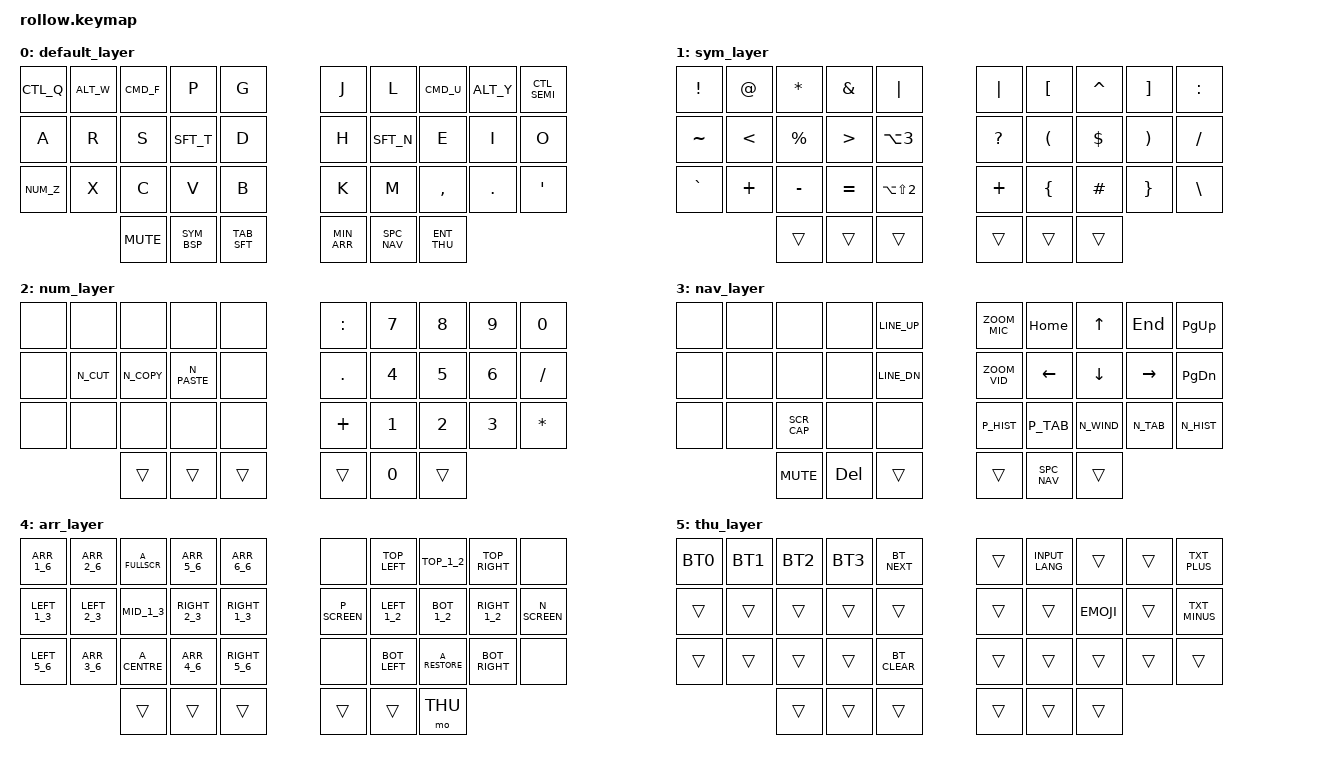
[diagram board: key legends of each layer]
#include <behaviors.dtsi>
#include <dt-bindings/zmk/keys.h>
#include <dt-bindings/zmk/bt.h>

#include "definitions.dtsi"
#include "homerow.dtsi"
#include "combos.dtsi"
#include "unicode.dtsi"
#include "tapdances.dtsi"

/ {
        chosen {
                zmk,matrix_transform = &five_column_transform;
        };

        keymap {
                compatible = "zmk,keymap";

                default_layer {
                        bindings = <
/**
 *      ,-----------------------------------------------------.         .------------------------------------------------------.
 *      |   Q     |    W     |    F     |    P     |    G     |         |    J     |    L     |    U     |    Y     |    ;     |
 *      |  CTRL   |   ALT    |   CMD    |          |          |         |          |          |   CMD    |   ALT    |   CTRL   |
 *      -------------------------------------------------------         --------------------------------------------------------
 *      |   A     |    R     |    S     |    T     |    D     |         |    H     |    N     |    E     |    I     |    O     |
 *      |         |          |          |  Shift   |          |         |          |  Shift   |          |          |          |
 *      -------------------------------------------------------         --------------------------------------------------------
 *      |   Z     |    X     |    C     |    V     |    B     |         |    K     |    M     |    ,     |    .     |    '     |
 *      |  NUM    |          |          |          |          |         |          |          |          |          |          |
 *      -------------------------------------------------------         --------------------------------------------------------
 *                           |   Mute   |   BSP    |   TAB    |         |    -     |  Space   | ENT_THU  |
 *                           |----------|   SYM    |   SFT    |         |   Arr    |   NAV    |----------|
 *                           |   Vol +  |---------------------'         `---------------------|  Right   |
 *                           |   Vol -  |                                                     |  Left    |
 *                           `----------'                                                     `----------'
 **/

        CTL_Q      ALT_W      CMD_F      &kp P      &kp G               &kp J      &kp L      CMD_U      ALT_Y      CTL_SEMI
        &kp A      &kp R      &kp S      SFT_T      &kp D               &kp H      SFT_N      &kp E      &kp I      &kp O
        NUM_Z      &kp X      &kp C      &kp V      &kp B               &kp K      &kp M      &kp COMMA  &kp DOT    &kp SQT
                              &kp C_MUTE SYM_BSP    TAB_SFT             MIN_ARR    SPC_NAV    ENT_THU
                        >;
                        sensor-bindings = <
                                &inc_dec_kp C_VOL_UP C_VOL_DN           &inc_dec_kp RIGHT LEFT
                        >;
                };
                
                sym_layer {
                        bindings = <
/**
 *      ,-----------------------------------------------------.         .------------------------------------------------------.
 *      |   !     |    @     |    *     |    &     |    |     |         |    |     |    [     |    ^     |    ]     |    :     |
 *      |         |          |          |          |          |         |          |          |          |          |          |
 *      -------------------------------------------------------         --------------------------------------------------------
 *      |   ~     |    <     |    %     |    >     |    £     |         |    ?     |    (     |    $     |    )     |    /     |
 *      |         |          |          |          |          |         |          |          |          |          |          |
 *      -------------------------------------------------------         --------------------------------------------------------
 *      |   `     |    +     |    -     |    =     |    €     |         |    +     |    {     |    #     |    }     |    \     |
 *      |         |          |          |          |          |         |          |          |          |          |          |
 *      -------------------------------------------------------         --------------------------------------------------------
 *                           |    NUM   |   BSP    |   TAB    |         |    -     |  Space   |  Enter   |
 *                           |----------|   SYM    |   SFT    |         |   Arr    |   NAV    |----------|
 *                           |    Up    |---------------------'         `---------------------| Page Up  |
 *                           |   Down   |                                                     | Page Down|
 *                           `----------'                                                     `----------'
 **/
 
        &kp EXCL   &kp AT     &kp ASTRK  &kp AMPS   &kp PIPE            &kp PIPE   &kp LBKT   &kp CARET  &kp RBKT   &kp COLON
        &kp TILDE  &kp LT     &kp PRCNT  &kp GT     &kp LA(N3)          &kp QMARK  &kp LPAR   &kp DLLR   &kp RPAR   &kp FSLH
        &kp GRAVE  &kp PLUS   &kp MINUS  &kp EQUAL  &kp LA(LS(N2))      &kp PLUS   &kp LBRC   &kp HASH   &kp RBRC   &kp BSLH
                              &trans     &trans     &trans              &trans     &trans     &trans
                        >;
                        sensor-bindings = <
                                &inc_dec_kp DOWN UP                     &inc_dec_kp PAGE_UP PAGE_DOWN
                        >;
                };

                num_layer {
                        bindings = <
/**
 *      ,-----------------------------------------------------.         .------------------------------------------------------.
 *      |         |          |          |          |          |         |    :     |    7     |    8     |    9     |    0     |
 *      |         |          |          |          |          |         |          |          |          |          |          |
 *      -------------------------------------------------------         --------------------------------------------------------
 *      |         |   CUT    |   COPY   |  PASTE   |          |         |    .     |    4     |    5     |    6     |    /     |
 *      |         |          |          |          |          |         |          |          |          |          |          |
 *      -------------------------------------------------------         --------------------------------------------------------
 *      |  NUM    |          |          |          |          |         |    +     |    1     |    2     |    3     |    *     |
 *      |         |          |          |          |          |         |          |          |          |          |          |
 *      -------------------------------------------------------         --------------------------------------------------------
 *                           |    NUM   |   BSP    |   TAB    |         |    -     |    0     |  Enter   |
 *                           |----------|   SYM    |   SFT    |         |   Arr    |          |----------|
 *                           |    Up    |---------------------'         `---------------------|  Right   |
 *                           |   Down   |                                                     |  Left    |
 *                           `----------'                                                     `----------'
 **/
 
        &none      &none      &none      &none      &none               &kp COLON  &kp N7     &kp N8     &kp N9     &kp N0 
        &none      N_CUT      N_COPY     N_PASTE    &none               &kp DOT    &kp N4     &kp N5     &kp N6     &kp FSLH 
        &none      &none      &none      &none      &none               &kp PLUS   &kp N1     &kp N2     &kp N3     &kp ASTRK
                              &trans     &trans     &trans              &trans     &kp N0     &trans
                        >;
                        sensor-bindings = <
                                &inc_dec_kp DOWN UP                     &inc_dec_kp RIGHT LEFT
                        >;
                };

                nav_layer {
                        bindings = <
/**
 *      ,-----------------------------------------------------.         .------------------------------------------------------.
 *      |         |          |          |          |  Xcode   |         |  Zoom    |   Home   |    Up    |   End    | Page Up  |
 *      |         |          |          |          |  Line Up |         |  Mic     |          |          |          |          |
 *      -------------------------------------------------------         --------------------------------------------------------
 *      |         |          |          |          |  Xcode   |         |  Zoom    |   Left   |   Down   |  Right   | Page Dn  |
 *      |         |          |          |          |  Line Dn |         |  Video   |          |          |          |          |
 *      -------------------------------------------------------         --------------------------------------------------------
 *      |         |          |  Screen  |          |          |         |  Prev    |   Prev   |   Next   |  Next    |   Next   |
 *      |         |          | Capture  |          |          |         | History  |   Tab    | Window   |  Tab     |  History |
 *      -------------------------------------------------------         --------------------------------------------------------
 *                           |  Mute    |   Del    |   TAB    |         |    -     |  Space   |  Enter   |
 *                           |----------|   FUN    |   SFT    |         |   Arr    |   NAV    |----------|
 *                           |  Vol +   |---------------------'         `---------------------|  Right   |
 *                           |  Vol -   |                                                     |  Left    |
 *                           `----------'                                                     `----------'
 **/

        &none      &none      &none      &none      LINE_UP             ZOOM_MIC   &kp HOME   &kp UP     &kp END    &kp PAGE_UP
        &none      &none      &none      &none      LINE_DN             ZOOM_VID   &kp LEFT   &kp DOWN   &kp RIGHT  &kp PAGE_DOWN
        &none      &none      SCR_CAP    &none      &none               P_HIST     P_TAB      N_WIND     N_TAB      N_HIST
                              &kp C_MUTE &kp DEL    &trans              &trans     SPC_NAV     &trans
                        >;
                        sensor-bindings = <
                                &inc_dec_kp C_VOL_UP C_VOL_DN           &inc_dec_kp RIGHT LEFT
                        >;
                };

                arr_layer {
                        bindings = <
 /**
 *      ,-----------------------------------------------------.         .------------------------------------------------------.
 *      |  1/6th  |  2/6th   |  Full    |  5/6th   |  6/6th   |         |          |   Top    |   Top    |   Top    |          |
 *      |         |          |  Screen  |          |          |         |          |   Left   |   Half   |  Right   |          |
 *      -------------------------------------------------------         --------------------------------------------------------
 *      | L 1/3rd | L 2/3rds | C 1/3rd  | R 2/3rds | R 1/3rd  |         |  Prev    |   Left   |   Down   |  Right   |  Next    |
 *      |         |          |          |          |          |         | Screen   |   Half   |          |  Half    |  Screen  |
 *      -------------------------------------------------------         --------------------------------------------------------
 *      | L 5/6th |  3/6th   |  Centre  |  4/6th   | R 5/6th  |         |          |  Bottom  |  Bottom  |  Bottom  |          |
 *      |         |          |          |          |          |         |          |  Left    |  Half    |  Right   |          |
 *      -------------------------------------------------------         --------------------------------------------------------
 *                           |  Mute    |   FUN    |   TAB    |         |    -     |  Space   |  Enter   |
 *                           |----------|          |   SFT    |         |   Arr    |   NAV    |----------|
 *                           |  Vol +   |---------------------'         `---------------------|  Right   |
 *                           |  Vol -   |                                                     |  Left    |
 *                           `----------'                                                     `----------'
 **/

        ARR_1_6    ARR_2_6    A_FULLSCR  ARR_5_6    ARR_6_6             &none      TOP_LEFT   TOP_1_2    TOP_RIGHT  &none
        LEFT_1_3   LEFT_2_3   MID_1_3    RIGHT_2_3  RIGHT_1_3           P_SCREEN   LEFT_1_2   BOT_1_2    RIGHT_1_2  N_SCREEN
        LEFT_5_6   ARR_3_6    A_CENTRE   ARR_4_6    RIGHT_5_6           &none      BOT_LEFT   A_RESTORE  BOT_RIGHT  &none
                              &trans     &trans     &trans              &trans     &trans     &mo THU
                        >;
                        sensor-bindings = <
                                &inc_dec_kp C_VOL_UP C_VOL_DN           &inc_dec_kp RIGHT LEFT
                        >;
                };

                thu_layer {
                        bindings = <
/**
 *      ,-----------------------------------------------------.         .------------------------------------------------------.
 *      | BT 0    |  BT 1    |   BT 2   |   BT 3   | BT NEXT  |         |          |  Input   |          |          |  Text +  |
 *      |         |          |          |          |          |         |          | Language |          |          |          |
 *      -------------------------------------------------------         --------------------------------------------------------
 *      |         |          |          |          |          |         |          |          |  EMOJI   |          |  Text -  |
 *      |         |          |          |          |          |         |          |          |          |          |          |
 *      -------------------------------------------------------         --------------------------------------------------------
 *      |         |          |          |          | BT Clear |         |          |          |          |          |          |
 *      |         |          |          |          |          |         |          |          |          |          |          |
 *      -------------------------------------------------------         --------------------------------------------------------
 *                           |          |          |          |         |          |          |          |
 *                           |----------|          |          |         |          |          |----------|
 *                           |          |---------------------'         `---------------------|          |
 *                           |          |                                                     |          |
 *                           `----------'                                                     `----------'
 **/

        BT0        BT1        BT2        BT3        BT_NEXT              &trans     INPUT_LANG &trans     &trans     TXT_PLUS
        &trans     &trans     &trans     &trans     &trans              &trans     &trans     EMOJI      &trans     TXT_MINUS
        &trans     &trans     &trans     &trans     BT_CLEAR            &trans     &trans     &trans     &trans     &trans
                              &trans     &trans     &trans              &trans     &trans     &trans
                        >;
                };
        };
};
